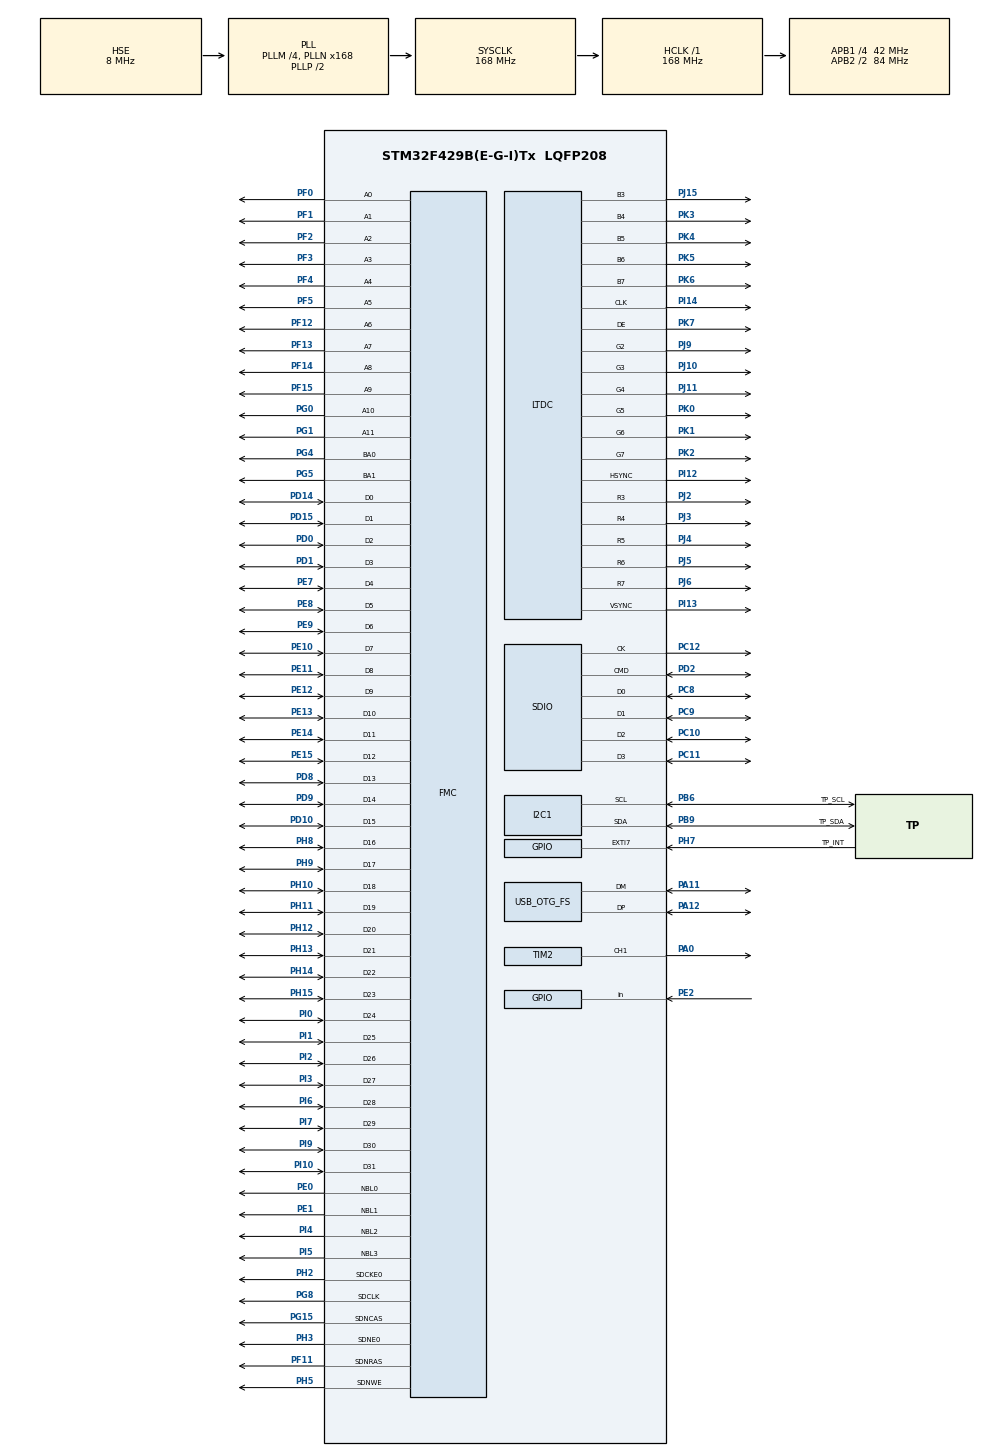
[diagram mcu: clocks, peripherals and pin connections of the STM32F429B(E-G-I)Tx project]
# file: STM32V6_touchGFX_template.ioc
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DMA2D.ColorMode=DMA2D_OUTPUT_RGB565
Dma.Request0=SDIO_RX
Dma.Request1=SDIO_TX
Dma.SDIO_RX.0.Direction=DMA_PERIPH_TO_MEMORY
Dma.SDIO_RX.0.FIFOMode=DMA_FIFOMODE_ENABLE
Dma.SDIO_RX.0.FIFOThreshold=DMA_FIFO_THRESHOLD_FULL
Dma.SDIO_RX.0.Instance=DMA2_Stream3
Dma.SDIO_RX.0.MemBurst=DMA_MBURST_INC4
Dma.SDIO_RX.0.MemDataAlignment=DMA_MDATAALIGN_WORD
Dma.SDIO_RX.0.MemInc=DMA_MINC_ENABLE
Dma.SDIO_RX.0.Mode=DMA_PFCTRL
Dma.SDIO_RX.0.PeriphBurst=DMA_PBURST_INC4
Dma.SDIO_RX.0.PeriphDataAlignment=DMA_PDATAALIGN_WORD
Dma.SDIO_RX.0.PeriphInc=DMA_PINC_DISABLE
Dma.SDIO_RX.0.Priority=DMA_PRIORITY_MEDIUM
Dma.SDIO_TX.1.Direction=DMA_MEMORY_TO_PERIPH
Dma.SDIO_TX.1.FIFOMode=DMA_FIFOMODE_ENABLE
Dma.SDIO_TX.1.FIFOThreshold=DMA_FIFO_THRESHOLD_FULL
Dma.SDIO_TX.1.Instance=DMA2_Stream6
Dma.SDIO_TX.1.MemBurst=DMA_MBURST_INC4
Dma.SDIO_TX.1.MemDataAlignment=DMA_MDATAALIGN_WORD
Dma.SDIO_TX.1.MemInc=DMA_MINC_ENABLE
Dma.SDIO_TX.1.Mode=DMA_PFCTRL
Dma.SDIO_TX.1.PeriphBurst=DMA_PBURST_INC4
Dma.SDIO_TX.1.PeriphDataAlignment=DMA_PDATAALIGN_WORD
Dma.SDIO_TX.1.PeriphInc=DMA_PINC_DISABLE
Dma.SDIO_TX.1.Priority=DMA_PRIORITY_HIGH
FATFS.BSP.number=1
FATFS0.BSP.STBoard=false
FATFS0.BSP.api=Unknown
FATFS0.BSP.instance=PE2
FATFS0.BSP.ip=GPIO
FATFS0.BSP.mode=Input
FATFS0.BSP.name=Detect_SDIO
FATFS0.BSP.solution=PE2
FMC.CASLatency1=FMC_SDRAM_CAS_LATENCY_2
FMC.ExitSelfRefreshDelay1=6
FMC.LoadToActiveDelay1=2
FMC.RCDDelay1=2
FMC.RPDelay1=2
FMC.ReadBurst1=FMC_SDRAM_RBURST_ENABLE
FMC.ReadPipeDelay1=FMC_SDRAM_RPIPE_DELAY_2
FMC.RowCycleDelay1=6
FMC.SDClockPeriod1=FMC_SDRAM_CLOCK_PERIOD_2
FMC.SelfRefreshTime1=4
FMC.WriteRecoveryTime1=2
FREERTOS.BinarySemaphores01=semGetPoint,Dynamic,NULL
FREERTOS.Tasks01=TouchGFX,8,2048,TouchGFX_Task,As weak,NULL,Dynamic,NULL,NULL;cmd_process,32,1024,cmd_process_Task,As weak,NULL,Dynamic,NULL,NULL;handWrite,24,1024,handWriteTask,As weak,NULL,Dynamic,NULL,NULL
FREERTOS.configTOTAL_HEAP_SIZE=32768
LTDC.ActiveW=800
LTDC.Alpha_L0=255
LTDC.Alpha_L1=255
LTDC.BlendingFactor1_L1=LTDC_BLENDING_FACTOR1_PAxCA
LTDC.BlendingFactor2_L1=LTDC_BLENDING_FACTOR2_PAxCA
LTDC.FBStartAdress_L0=LTDC_L0_ADDR
LTDC.FBStartAdress_L1=LTDC_L1_ADDR
LTDC.HBP=46
LTDC.HFP=210
LTDC.HSync=6
LTDC.ImageHeight_L0=LTDC_L0_HEIGHT
LTDC.ImageHeight_L1=LTDC_L1_HEIGHT
LTDC.ImageWidth_L0=LTDC_L0_WIDTH
LTDC.ImageWidth_L1=LTDC_L1_WIDTH
LTDC.Layers=1
LTDC.PixelFormat_L0=LTDC_PIXEL_FORMAT_RGB565
LTDC.PixelFormat_L1=LTDC_PIXEL_FORMAT_AL44
LTDC.VBP=23
LTDC.VFP=22
LTDC.VSync=6
LTDC.WindowX0_L1=LTDC_L1_START_X
LTDC.WindowX1_L0=LTDC_L0_WIDTH
LTDC.WindowX1_L1=(LTDC_L1_START_X + LTDC_L1_WIDTH)
LTDC.WindowY0_L1=LTDC_L1_START_Y
LTDC.WindowY1_L0=LTDC_L0_HEIGHT
LTDC.WindowY1_L1=(LTDC_L1_START_Y + LTDC_L1_HEIGHT)
Mcu.Family=STM32F4
Mcu.Name=STM32F429B(E-G-I)Tx
Mcu.Package=LQFP208
Mcu.UserConstants=LTDC_L1_ADDR,(LTDC_L0_ADDR + LTDC_L0_WIDTH * LTDC_L0_HEIGHT * 2 * 2);LTDC_L1_WIDTH,300;LTDC_L1_START_X,430;LTDC_L0_WIDTH,800;LTDC_L0_ADDR,0xC0000000;LTDC_L1_START_Y,90;LTDC_L0_HEIGHT,480;LTDC_L1_HEIGHT,300
NVIC.DMA2D_IRQn=true\:12\:0\:true\:false\:true\:true\:true\:true\:true
NVIC.DMA2_Stream3_IRQn=true\:6\:0\:true\:false\:true\:true\:false\:true\:true
NVIC.DMA2_Stream6_IRQn=true\:5\:0\:false\:false\:true\:true\:false\:true\:true
NVIC.LTDC_IRQn=true\:13\:0\:true\:false\:true\:true\:true\:true\:true
NVIC.OTG_FS_IRQn=true\:10\:0\:true\:false\:true\:true\:false\:true\:true
NVIC.PriorityGroup=NVIC_PRIORITYGROUP_4
NVIC.SDIO_IRQn=true\:5\:0\:false\:false\:true\:true\:true\:true\:true
NVIC.TIM6_DAC_IRQn=true\:15\:0\:false\:false\:true\:false\:false\:true\:true
NVIC.TimeBase=TIM6_DAC_IRQn
NVIC.TimeBaseIP=TIM6
PA0/WKUP.Signal=S_TIM2_CH1_ETR
PA11.Mode=Device_Only
PA11.Signal=USB_OTG_FS_DM
PA12.GPIO_PuPd=GPIO_PULLUP
PA12.Mode=Device_Only
PA12.Signal=USB_OTG_FS_DP
PA13.Mode=Serial_Wire
PA13.Signal=SYS_JTMS-SWDIO
PA14.Mode=Serial_Wire
PA14.Signal=SYS_JTCK-SWCLK
PB6.GPIO_Label=TP_SCL
PB6.GPIO_Pu=GPIO_PULLUP
PB6.Mode=I2C
PB6.Signal=I2C1_SCL
PB9.GPIO_Label=TP_SDA
PB9.GPIO_Pu=GPIO_PULLUP
PB9.Mode=I2C
PB9.Signal=I2C1_SDA
PC10.Mode=SD_4_bits_Wide_bus
PC10.Signal=SDIO_D2
PC11.Mode=SD_4_bits_Wide_bus
PC11.Signal=SDIO_D3
PC12.Mode=SD_4_bits_Wide_bus
PC12.Signal=SDIO_CK
PC8.Mode=SD_4_bits_Wide_bus
PC8.Signal=SDIO_D0
PC9.Mode=SD_4_bits_Wide_bus
PC9.Signal=SDIO_D1
PD0.Signal=FMC_D2_DA2
PD1.Signal=FMC_D3_DA3
PD10.Signal=FMC_D15_DA15
PD14.Signal=FMC_D0_DA0
PD15.Signal=FMC_D1_DA1
PD2.Mode=SD_4_bits_Wide_bus
PD2.Signal=SDIO_CMD
PD8.Signal=FMC_D13_DA13
PD9.Signal=FMC_D14_DA14
PE0.Signal=FMC_NBL0
PE1.Signal=FMC_NBL1
PE10.Signal=FMC_D7_DA7
PE11.Signal=FMC_D8_DA8
PE12.Signal=FMC_D9_DA9
PE13.Signal=FMC_D10_DA10
PE14.Signal=FMC_D11_DA11
PE15.Signal=FMC_D12_DA12
PE2.Signal=GPIO_Input
PE7.Signal=FMC_D4_DA4
PE8.Signal=FMC_D5_DA5
PE9.Signal=FMC_D6_DA6
PF0.Signal=FMC_A0
PF1.Signal=FMC_A1
PF11.Signal=FMC_SDNRAS
PF12.Signal=FMC_A6
PF13.Signal=FMC_A7
PF14.Signal=FMC_A8
PF15.Signal=FMC_A9
PF2.Signal=FMC_A2
PF3.Signal=FMC_A3
PF4.Signal=FMC_A4
PF5.Signal=FMC_A5
PG0.Signal=FMC_A10
PG1.Signal=FMC_A11
PG15.Signal=FMC_SDNCAS
PG4.Signal=FMC_A14_BA0
PG5.Signal=FMC_A15_BA1
PG8.Signal=FMC_SDCLK
PH0/OSC_IN.Mode=HSE-External-Oscillator
PH0/OSC_IN.Signal=RCC_OSC_IN
PH1/OSC_OUT.Mode=HSE-External-Oscillator
PH1/OSC_OUT.Signal=RCC_OSC_OUT
PH10.Signal=FMC_D18
PH11.Signal=FMC_D19
PH12.Signal=FMC_D20
PH13.Signal=FMC_D21
PH14.Signal=FMC_D22
PH15.Signal=FMC_D23
PH2.Mode=SdramChipSelect1_1
PH2.Signal=FMC_SDCKE0
PH3.Mode=SdramChipSelect1_1
PH3.Signal=FMC_SDNE0
PH5.Signal=FMC_SDNWE
PH7.GPIO_Label=TP_INT
PH7.GPIO_PuPd=GPIO_PULLDOWN
PH7.Signal=GPXTI7
PH8.Signal=FMC_D16
PH9.Signal=FMC_D17
PI0.Signal=FMC_D24
PI1.Signal=FMC_D25
PI10.Signal=FMC_D31
PI12.GPIO_Speed=GPIO_SPEED_FREQ_VERY_HIGH
PI12.Mode=RGB565
PI12.Signal=LTDC_HSYNC
PI13.GPIO_Speed=GPIO_SPEED_FREQ_VERY_HIGH
PI13.Mode=RGB565
PI13.Signal=LTDC_VSYNC
PI14.GPIO_Speed=GPIO_SPEED_FREQ_VERY_HIGH
PI14.Mode=RGB565
PI14.Signal=LTDC_CLK
PI2.Signal=FMC_D26
PI3.Signal=FMC_D27
PI4.Signal=FMC_NBL2
PI5.Signal=FMC_NBL3
PI6.Signal=FMC_D28
PI7.Signal=FMC_D29
PI9.Signal=FMC_D30
PJ10.GPIO_Speed=GPIO_SPEED_FREQ_VERY_HIGH
PJ10.Mode=RGB565
PJ10.Signal=LTDC_G3
PJ11.GPIO_Speed=GPIO_SPEED_FREQ_VERY_HIGH
PJ11.Mode=RGB565
PJ11.Signal=LTDC_G4
PJ15.GPIO_Speed=GPIO_SPEED_FREQ_VERY_HIGH
PJ15.Mode=RGB565
PJ15.Signal=LTDC_B3
PJ2.GPIO_Speed=GPIO_SPEED_FREQ_VERY_HIGH
PJ2.Mode=RGB565
PJ2.Signal=LTDC_R3
PJ3.GPIO_Speed=GPIO_SPEED_FREQ_VERY_HIGH
PJ3.Mode=RGB565
PJ3.Signal=LTDC_R4
PJ4.GPIO_Speed=GPIO_SPEED_FREQ_VERY_HIGH
PJ4.Mode=RGB565
PJ4.Signal=LTDC_R5
PJ5.GPIO_Speed=GPIO_SPEED_FREQ_VERY_HIGH
PJ5.Mode=RGB565
PJ5.Signal=LTDC_R6
PJ6.GPIO_Speed=GPIO_SPEED_FREQ_VERY_HIGH
PJ6.Mode=RGB565
PJ6.Signal=LTDC_R7
PJ9.GPIO_Speed=GPIO_SPEED_FREQ_VERY_HIGH
PJ9.Mode=RGB565
PJ9.Signal=LTDC_G2
PK0.GPIO_Speed=GPIO_SPEED_FREQ_VERY_HIGH
PK0.Mode=RGB565
PK0.Signal=LTDC_G5
PK1.GPIO_Speed=GPIO_SPEED_FREQ_VERY_HIGH
PK1.Mode=RGB565
PK1.Signal=LTDC_G6
PK2.GPIO_Speed=GPIO_SPEED_FREQ_VERY_HIGH
PK2.Mode=RGB565
PK2.Signal=LTDC_G7
PK3.GPIO_Speed=GPIO_SPEED_FREQ_VERY_HIGH
PK3.Mode=RGB565
PK3.Signal=LTDC_B4
PK4.GPIO_Speed=GPIO_SPEED_FREQ_VERY_HIGH
PK4.Mode=RGB565
PK4.Signal=LTDC_B5
PK5.GPIO_Speed=GPIO_SPEED_FREQ_VERY_HIGH
PK5.Mode=RGB565
PK5.Signal=LTDC_B6
PK6.GPIO_Speed=GPIO_SPEED_FREQ_VERY_HIGH
PK6.Mode=RGB565
PK6.Signal=LTDC_B7
PK7.GPIO_Speed=GPIO_SPEED_FREQ_VERY_HIGH
PK7.Mode=RGB565
PK7.Signal=LTDC_DE
ProjectManager.HeapSize=0x400
ProjectManager.StackSize=0x2000
ProjectManager.TargetToolchain=MDK-ARM V5.32
RCC.48MHZClocksFreq_Value=48000000
RCC.AHBFreq_Value=168000000
RCC.APB1CLKDivider=RCC_HCLK_DIV4
RCC.APB1Freq_Value=42000000
RCC.APB1TimFreq_Value=84000000
RCC.APB2CLKDivider=RCC_HCLK_DIV2
RCC.APB2Freq_Value=84000000
RCC.APB2TimFreq_Value=168000000
RCC.CortexFreq_Value=168000000
RCC.HCLKFreq_Value=168000000
RCC.HSE_VALUE=8000000
RCC.HSI_VALUE=16000000
RCC.LSE_VALUE=32768
RCC.PLLM=4
RCC.PLLN=168
RCC.PLLQ=7
RCC.PLLSAIN=68
RCC.SYSCLKFreq_VALUE=168000000
RCC.SYSCLKSource=RCC_SYSCLKSOURCE_PLLCLK
RCC.VCOOutputFreq_Value=336000000
SH.FMC_A0.0=FMC_A0,12b-sda1
SH.FMC_A1.0=FMC_A1,12b-sda1
SH.FMC_A10.0=FMC_A10,12b-sda1
SH.FMC_A11.0=FMC_A11,12b-sda1
SH.FMC_A14_BA0.0=FMC_BA0,FourSdramBanks1
SH.FMC_A15_BA1.0=FMC_BA1,FourSdramBanks1
SH.FMC_A2.0=FMC_A2,12b-sda1
SH.FMC_A3.0=FMC_A3,12b-sda1
SH.FMC_A4.0=FMC_A4,12b-sda1
SH.FMC_A5.0=FMC_A5,12b-sda1
SH.FMC_A6.0=FMC_A6,12b-sda1
SH.FMC_A7.0=FMC_A7,12b-sda1
SH.FMC_A8.0=FMC_A8,12b-sda1
SH.FMC_A9.0=FMC_A9,12b-sda1
SH.FMC_D0_DA0.0=FMC_D0,sd-32b-d1
SH.FMC_D10_DA10.0=FMC_D10,sd-32b-d1
SH.FMC_D11_DA11.0=FMC_D11,sd-32b-d1
SH.FMC_D12_DA12.0=FMC_D12,sd-32b-d1
SH.FMC_D13_DA13.0=FMC_D13,sd-32b-d1
SH.FMC_D14_DA14.0=FMC_D14,sd-32b-d1
SH.FMC_D15_DA15.0=FMC_D15,sd-32b-d1
SH.FMC_D16.0=FMC_D16,sd-32b-d1
SH.FMC_D17.0=FMC_D17,sd-32b-d1
SH.FMC_D18.0=FMC_D18,sd-32b-d1
SH.FMC_D19.0=FMC_D19,sd-32b-d1
SH.FMC_D1_DA1.0=FMC_D1,sd-32b-d1
SH.FMC_D20.0=FMC_D20,sd-32b-d1
SH.FMC_D21.0=FMC_D21,sd-32b-d1
SH.FMC_D22.0=FMC_D22,sd-32b-d1
SH.FMC_D23.0=FMC_D23,sd-32b-d1
SH.FMC_D24.0=FMC_D24,sd-32b-d1
SH.FMC_D25.0=FMC_D25,sd-32b-d1
SH.FMC_D26.0=FMC_D26,sd-32b-d1
SH.FMC_D27.0=FMC_D27,sd-32b-d1
SH.FMC_D28.0=FMC_D28,sd-32b-d1
SH.FMC_D29.0=FMC_D29,sd-32b-d1
SH.FMC_D2_DA2.0=FMC_D2,sd-32b-d1
SH.FMC_D30.0=FMC_D30,sd-32b-d1
SH.FMC_D31.0=FMC_D31,sd-32b-d1
SH.FMC_D3_DA3.0=FMC_D3,sd-32b-d1
SH.FMC_D4_DA4.0=FMC_D4,sd-32b-d1
SH.FMC_D5_DA5.0=FMC_D5,sd-32b-d1
SH.FMC_D6_DA6.0=FMC_D6,sd-32b-d1
SH.FMC_D7_DA7.0=FMC_D7,sd-32b-d1
SH.FMC_D8_DA8.0=FMC_D8,sd-32b-d1
SH.FMC_D9_DA9.0=FMC_D9,sd-32b-d1
SH.FMC_NBL0.0=FMC_NBL0,Sd4ByteEnable1
SH.FMC_NBL1.0=FMC_NBL1,Sd4ByteEnable1
SH.FMC_NBL2.0=FMC_NBL2,Sd4ByteEnable1
SH.FMC_NBL3.0=FMC_NBL3,Sd4ByteEnable1
SH.FMC_SDCLK.0=FMC_SDCLK,12b-sda1
SH.FMC_SDNCAS.0=FMC_SDNCAS,12b-sda1
SH.FMC_SDNRAS.0=FMC_SDNRAS,12b-sda1
SH.FMC_SDNWE.0=FMC_SDNWE,12b-sda1
SH.S_TIM2_CH1_ETR.0=TIM2_CH1,PWM Generation1 CH1
STMicroelectronics.X-CUBE-TOUCHGFX.4.23.2.ApplicationCcGraphicsJjApplication=TouchGFXOoGenerator
STMicroelectronics.X-CUBE-TOUCHGFX.4.23.2.tgfx_address1=0xC0000000
STMicroelectronics.X-CUBE-TOUCHGFX.4.23.2.tgfx_address2=0xC00BB800
STMicroelectronics.X-CUBE-TOUCHGFX.4.23.2.tgfx_buffering_strategy=Double
STMicroelectronics.X-CUBE-TOUCHGFX.4.23.2.tgfx_display_interface=disp_ltdc
STMicroelectronics.X-CUBE-TOUCHGFX.4.23.2.tgfx_hardware_accelerator=dma_2d
STMicroelectronics.X-CUBE-TOUCHGFX.4.23.2.tgfx_location=By Address
STMicroelectronics.X-CUBE-TOUCHGFX.4.23.2.tgfx_vsync=vsync_ltdc
STMicroelectronics.X-CUBE-TOUCHGFX.4.23.2_IsPackSelfContextualization=true
TIM2.AutoReloadPreload=TIM_AUTORELOAD_PRELOAD_ENABLE
TIM2.Channel-PWM\ Generation1\ CH1=TIM_CHANNEL_1
TIM2.Period=100-1
TIM2.Prescaler=84-1
TIM2.Pulse-PWM\ Generation1\ CH1=50-1
USB_DEVICE.CLASS_NAME_FS=MSC
USB_DEVICE.VirtualMode-MSC_FS=Msc
USB_DEVICE.VirtualModeFS=Msc_FS
USB_OTG_FS.VirtualMode=Device_Only
VP_CRC_VS_CRC.Mode=CRC_Activate
VP_DMA2D_VS_DMA2D.Mode=DMA2D_Activate
VP_FATFS_VS_SDIO.Mode=SDIO
VP_FREERTOS_VS_CMSIS_V2.Mode=CMSIS_V2
VP_STMicroelectronics.X-CUBE-TOUCHGFX_VS_GraphicsJjApplication_4.23.2.Mode=GraphicsJjApplication
VP_SYS_VS_tim6.Mode=TIM6
VP_TIM2_VS_ClockSourceINT.Mode=Internal
VP_USB_DEVICE_VS_USB_DEVICE_MSC_FS.Mode=MSC_FS
board=custom

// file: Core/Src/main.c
/* USER CODE BEGIN Header */
/**
  ******************************************************************************
  * @file           : main.c
  * @brief          : Main program body
  ******************************************************************************
  * @attention
  *
  * Copyright (c) 2024 STMicroelectronics.
  * All rights reserved.
  *
  * This software is licensed under terms that can be found in the LICENSE file
  * in the root directory of this software component.
  * If no LICENSE file comes with this software, it is provided AS-IS.
  *
  ******************************************************************************
  */
/* USER CODE END Header */
#include "main.h"
#include "cmsis_os.h"
#include "crc.h"
#include "dma.h"
#include "dma2d.h"
#include "fatfs.h"
#include "i2c.h"
#include "ltdc.h"
#include "sdio.h"
#include "tim.h"
#include "gpio.h"
#include "fmc.h"
#include "app_touchgfx.h"

/* USER CODE BEGIN Includes */
#include "dbger.h"
#include "gt911.h"
/* USER CODE END Includes */

void SystemClock_Config(void);
void MX_FREERTOS_Init(void);

int main(void)
{

  /* MCU Configuration--------------------------------------------------------*/

  /* Reset of all peripherals, Initializes the Flash interface and the Systick. */
  HAL_Init();

  /* Configure the system clock */
  SystemClock_Config();

  /* USER CODE BEGIN SysInit */
	LOG_INIT();
	LOG_DBG("\n\nSTM32V6 F429 AI hand write demo...\n");
  /* USER CODE END SysInit */

  /* Initialize all configured peripherals */
  MX_GPIO_Init();
  MX_DMA_Init();
  MX_CRC_Init();
  MX_DMA2D_Init();
  MX_I2C1_Init();
  MX_FMC_Init();
  MX_LTDC_Init();
  MX_SDIO_SD_Init();
  MX_FATFS_Init();
  MX_TIM2_Init();
  MX_TouchGFX_Init();
  /* Call PreOsInit function */
  MX_TouchGFX_PreOSInit();
  /* USER CODE BEGIN 2 */
	memset((void*)LTDC_L1_ADDR, 0xFF, LTDC_L1_WIDTH * LTDC_L1_HEIGHT);
  /* USER CODE END 2 */

  /* Init scheduler */
  osKernelInitialize();

  /* Call init function for freertos objects (in cmsis_os2.c) */
  MX_FREERTOS_Init();

  /* Start scheduler */
  osKernelStart();

  /* We should never get here as control is now taken by the scheduler */

  /* Infinite loop */
  while (1)
  {

  }
}

void SystemClock_Config(void)
{
  RCC_OscInitTypeDef RCC_OscInitStruct = {0};
  RCC_ClkInitTypeDef RCC_ClkInitStruct = {0};

  /** Configure the main internal regulator output voltage
  */
  __HAL_RCC_PWR_CLK_ENABLE();
  __HAL_PWR_VOLTAGESCALING_CONFIG(PWR_REGULATOR_VOLTAGE_SCALE1);

  /** Initializes the RCC Oscillators according to the specified parameters
  * in the RCC_OscInitTypeDef structure.
  */
  RCC_OscInitStruct.OscillatorType = RCC_OSCILLATORTYPE_HSE;
  RCC_OscInitStruct.HSEState = RCC_HSE_ON;
  RCC_OscInitStruct.PLL.PLLState = RCC_PLL_ON;
  RCC_OscInitStruct.PLL.PLLSource = RCC_PLLSOURCE_HSE;
  RCC_OscInitStruct.PLL.PLLM = 4;
  RCC_OscInitStruct.PLL.PLLN = 168;
  RCC_OscInitStruct.PLL.PLLP = RCC_PLLP_DIV2;
  RCC_OscInitStruct.PLL.PLLQ = 7;
  if (HAL_RCC_OscConfig(&RCC_OscInitStruct) != HAL_OK)
  {
    Error_Handler();
  }

  /** Initializes the CPU, AHB and APB buses clocks
  */
  RCC_ClkInitStruct.ClockType = RCC_CLOCKTYPE_HCLK|RCC_CLOCKTYPE_SYSCLK
                              |RCC_CLOCKTYPE_PCLK1|RCC_CLOCKTYPE_PCLK2;
  RCC_ClkInitStruct.SYSCLKSource = RCC_SYSCLKSOURCE_PLLCLK;
  RCC_ClkInitStruct.AHBCLKDivider = RCC_SYSCLK_DIV1;
  RCC_ClkInitStruct.APB1CLKDivider = RCC_HCLK_DIV4;
  RCC_ClkInitStruct.APB2CLKDivider = RCC_HCLK_DIV2;

  if (HAL_RCC_ClockConfig(&RCC_ClkInitStruct, FLASH_LATENCY_5) != HAL_OK)
  {
    Error_Handler();
  }
}

void HAL_TIM_PeriodElapsedCallback(TIM_HandleTypeDef *htim)
{
  if (htim->Instance == TIM6) {
    HAL_IncTick();
  }
}

void Error_Handler(void)
{
  __disable_irq();
  while (1)
  {
  }
}

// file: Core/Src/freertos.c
/* USER CODE BEGIN Header */
/**
  ******************************************************************************
  * File Name          : freertos.c
  * Description        : Code for freertos applications
  ******************************************************************************
  * @attention
  *
  * Copyright (c) 2024 STMicroelectronics.
  * All rights reserved.
  *
  * This software is licensed under terms that can be found in the LICENSE file
  * in the root directory of this software component.
  * If no LICENSE file comes with this software, it is provided AS-IS.
  *
  ******************************************************************************
  */
/* USER CODE END Header */

#include "FreeRTOS.h"
#include "task.h"
#include "main.h"
#include "cmsis_os.h"

/* USER CODE BEGIN Includes */
#include "dbger.h"
#include "gt911.h"
#include "usb_device.h"
#include "fatfs_file_handler.h"
#include "atk_ncr.h"
/* USER CODE END Includes */

/* USER CODE BEGIN Variables */
StoreDisk_t sDisk[_VOLUMES] = {
	// path       FATFS       FIL        opt     mCnt
	{SDPath, 	&SDFatFS, 	&SDFile, 	FM_FAT32, 0},		// SDcard disk
	//{USERPath, 	&USERFatFS, &USERFile, 	FM_FAT,   0}		// SpiFlash disk
};

extern TIM_HandleTypeDef htim2;
extern LTDC_HandleTypeDef hltdc;
/* USER CODE END Variables */
/* Definitions for TouchGFX */
osThreadId_t TouchGFXHandle;
const osThreadAttr_t TouchGFX_attributes = {
  .name = "TouchGFX",
  .stack_size = 2048 * 4,
  .priority = (osPriority_t) osPriorityLow,
};
/* Definitions for cmd_process */
osThreadId_t cmd_processHandle;
const osThreadAttr_t cmd_process_attributes = {
  .name = "cmd_process",
  .stack_size = 1024 * 4,
  .priority = (osPriority_t) osPriorityAboveNormal,
};
/* Definitions for handWrite */
osThreadId_t handWriteHandle;
const osThreadAttr_t handWrite_attributes = {
  .name = "handWrite",
  .stack_size = 1024 * 4,
  .priority = (osPriority_t) osPriorityNormal,
};
/* Definitions for semGetPoint */
osSemaphoreId_t semGetPointHandle;
const osSemaphoreAttr_t semGetPoint_attributes = {
  .name = "semGetPoint"
};

/* USER CODE BEGIN FunctionPrototypes */
void LTDC_draw_line(int16_t x1, int16_t y1, int16_t x2, int16_t y2, uint8_t width);
/* USER CODE END FunctionPrototypes */

void TouchGFX_Task(void *argument);
void cmd_process_Task(void *argument);
void handWriteTask(void *argument);

void MX_FREERTOS_Init(void); /* (MISRA C 2004 rule 8.1) */

void MX_FREERTOS_Init(void) {

  /* Create the semaphores(s) */
  /* creation of semGetPoint */
  semGetPointHandle = osSemaphoreNew(1, 0, &semGetPoint_attributes);

  /* Create the thread(s) */
  /* creation of TouchGFX */
  TouchGFXHandle = osThreadNew(TouchGFX_Task, NULL, &TouchGFX_attributes);

  /* creation of cmd_process */
  cmd_processHandle = osThreadNew(cmd_process_Task, NULL, &cmd_process_attributes);

  /* creation of handWrite */
  handWriteHandle = osThreadNew(handWriteTask, NULL, &handWrite_attributes);

}

__weak void TouchGFX_Task(void *argument)
{
  for(;;)
  {
    osDelay(1);
  }
}

__weak void cmd_process_Task(void *argument)
{
  /* USER CODE BEGIN cmd_process_Task */
	GT911_STA_t gt911_sta = GT911_STA_OK;
	//HAL_NVIC_DisableIRQ(EXTI9_5_IRQn);		// delete it if GT911 is NOT work in interrupt mode;
	gt911_sta = gt911_init();
	if(GT911_STA_OK != gt911_sta) {
		LOG_ERR("GT911 init err[%d]\n", gt911_sta);
	} else {
		LOG_DBG("GT911 init OK\n");
		//HAL_NVIC_EnableIRQ(EXTI9_5_IRQn);		// delete it if GT911 is NOT work in interrupt mode;
	}

	FH_mount(&sDisk[0]);
	FH_scan(&sDisk[0], NULL);
	MX_USB_DEVICE_Init();

	osDelay(1000);	// wait for screen be stable
	HAL_TIM_PWM_Start(&htim2, TIM_CHANNEL_1);
	__HAL_TIM_SET_COMPARE(&htim2, TIM_CHANNEL_1, 100);

	alientek_ncr_init();

	osSemaphoreRelease(semGetPointHandle);

//	for(uint32_t i = 0; i < 90000; i++) {
//		*((uint8_t*)LTDC_L1_ADDR + i) = 0xF0 + (i / 600) % 0x10;
//	}

  /* Infinite loop */
  for(;;)
  {
	  osDelay(1);

//	  osDelay(1000);
//	  HAL_LTDC_SetAlpha(&hltdc, 0, LTDC_LAYER_2);
//	  osDelay(1000);
//	  HAL_LTDC_SetAlpha(&hltdc, 255, LTDC_LAYER_2);

  }
  /* USER CODE END cmd_process_Task */
}

__weak void handWriteTask(void *argument)
{
  /* USER CODE BEGIN handWriteTask */
  /* Infinite loop */
	for(;;)
	{
		osSemaphoreAcquire(semGetPointHandle, osWaitForever);
		gt911_get_touch(touch_coordinate, &num_touched);
		if(num_touched == 0) {
			osDelay(2);
			osSemaphoreRelease(semGetPointHandle);
		} else {
			//LOG_DBG("point(%d, %d)\n", touch_coordinate[0].x, touch_coordinate[0].y);
			if(touch_coordinate[0].x > LTDC_L1_START_X && touch_coordinate[0].x < LTDC_L1_START_X + LTDC_L1_WIDTH &&
				 touch_coordinate[0].y > LTDC_L1_START_Y && touch_coordinate[0].y < LTDC_L1_START_Y + LTDC_L1_HEIGHT)
			{
				static COORDINATE_t last_point = {.x = 0, .y = 0};
				static uint32_t last_point_tick = 0;
				if(last_point.x == touch_coordinate[0].x && last_point.y == touch_coordinate[0].y) {
					last_point_tick = HAL_GetTick();
				} else {
					#if 0		// coordinate turn 90 dgr test
					int16_t temp = touch_coordinate[0].x;
					touch_coordinate[0].x = (touch_coordinate[0].y - 240) + 350;
					touch_coordinate[0].y = (350 - temp + 240);
					#endif

					uint32_t now = HAL_GetTick();
					if(now - last_point_tick > 20) {
						last_point.x = touch_coordinate[0].x;
						last_point.y = touch_coordinate[0].y;
					} else {
						// draw line
						#define LINE_WIDTH	2
						//LOG_DBG("(%d, %d) --> (%d, %d)\n", last_point.x, last_point.y, touch_coordinate[0].x, touch_coordinate[0].y);
						if(last_point.x < LTDC_L1_START_X + LINE_WIDTH) {
							last_point.x = LTDC_L1_START_X + LINE_WIDTH;
						}
						if(last_point.x > LTDC_L1_START_X + LTDC_L1_WIDTH - LINE_WIDTH) {
							last_point.x = LTDC_L1_START_X + LTDC_L1_WIDTH - LINE_WIDTH;
						}
						if(last_point.y < LTDC_L1_START_Y + LINE_WIDTH) {
							last_point.y = LTDC_L1_START_Y + LINE_WIDTH;
						}
						if(last_point.y > LTDC_L1_START_Y + LTDC_L1_HEIGHT - LINE_WIDTH) {
							last_point.y = LTDC_L1_START_Y + LTDC_L1_HEIGHT - LINE_WIDTH;
						}
						if(touch_coordinate[0].x < LTDC_L1_START_X + LINE_WIDTH) {
							touch_coordinate[0].x = LTDC_L1_START_X + LINE_WIDTH;
						}
						if(touch_coordinate[0].x > LTDC_L1_START_X + LTDC_L1_WIDTH - LINE_WIDTH) {
							touch_coordinate[0].x = LTDC_L1_START_X + LTDC_L1_WIDTH - LINE_WIDTH;
						}
						if(touch_coordinate[0].y < LTDC_L1_START_Y + LINE_WIDTH) {
							touch_coordinate[0].y = LTDC_L1_START_Y + LINE_WIDTH;
						}
						if(touch_coordinate[0].y > LTDC_L1_START_Y + LTDC_L1_HEIGHT - LINE_WIDTH) {
							touch_coordinate[0].y = LTDC_L1_START_Y + LTDC_L1_HEIGHT - LINE_WIDTH;
						}
						//LOG_DBG("line:(%d, %d) -> (%d, %d)\n", last_point.x, last_point.y, touch_coordinate[0].x, touch_coordinate[0].y);
						LTDC_draw_line(last_point.x, last_point.y, touch_coordinate[0].x, touch_coordinate[0].y, LINE_WIDTH);
						//HAL_LTDC_SetAlpha(&hltdc, 255, LTDC_LAYER_2);
						last_point.x = touch_coordinate[0].x;
						last_point.y = touch_coordinate[0].y;
						if(point_num > MAX_POINT - 20) {
							LOG_WAR("MAX_POINT[%d] too small\n", MAX_POINT);
						}
					}
					last_point_tick = now;
				}
				osSemaphoreRelease(semGetPointHandle);
			}
		}
	}
  /* USER CODE END handWriteTask */
}
